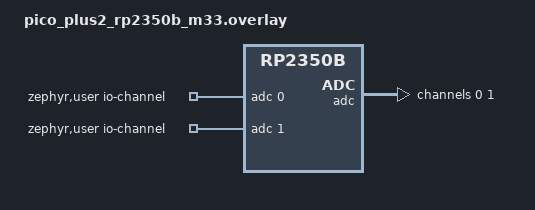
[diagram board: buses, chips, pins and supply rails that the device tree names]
/*
 * Copyright (c) 2023 Tokita, Hiroshi <tokita.hiroshi@fujitsu.com>
 *
 * SPDX-License-Identifier: Apache-2.0
 */

tst_dma0: &dma {
	status = "okay";
};

/ {
	zephyr,user {
		io-channels = <&adc 0>, <&adc 1>;
	};
};

&adc {
	status = "okay";
	#address-cells = <1>;
	#size-cells = <0>;
	channel@0 {
		reg = <0>;
		zephyr,gain = "ADC_GAIN_1";
		zephyr,reference = "ADC_REF_INTERNAL";
		zephyr,acquisition-time = <ADC_ACQ_TIME_DEFAULT>;
		zephyr,resolution = <12>;
	};
	channel@1 {
		reg = <1>;
		zephyr,gain = "ADC_GAIN_1";
		zephyr,reference = "ADC_REF_INTERNAL";
		zephyr,acquisition-time = <ADC_ACQ_TIME_DEFAULT>;
		zephyr,resolution = <12>;
	};
};

#include "rpi_pico.overlay"
